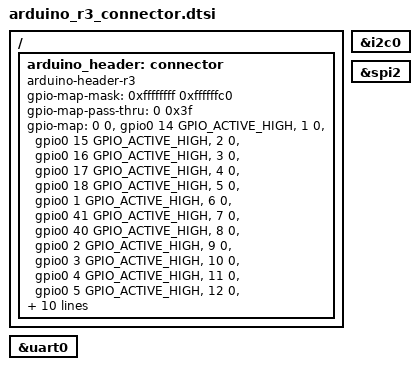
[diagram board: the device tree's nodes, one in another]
/*
 * Copyright 2023 Google LLC
 *
 * SPDX-License-Identifier: Apache-2.0
 */

/ {
	arduino_header: connector {
		/*
		* Note: UART pins TX and RX are swapped on this board
		* compared to the original Arduino Uno R3 header.
		* This file complies with the names in the silkscreen
		* and official Adafruit documentation, and must be
		* corrected with an overlay in cases where interfacing
		* with compatible Arduino shields that use UART.
		*/
		compatible = "arduino-header-r3";
		#gpio-cells = <2>;
		gpio-map-mask = <0xffffffff 0xffffffc0>;
		gpio-map-pass-thru = <0 0x3f>;
		gpio-map = <0  0 &gpio0 14 GPIO_ACTIVE_HIGH>, /* A0 */
		<1  0 &gpio0 15 GPIO_ACTIVE_HIGH>, /* A1 */
		<2  0 &gpio0 16 GPIO_ACTIVE_HIGH>, /* A2 */
		<3  0 &gpio0 17 GPIO_ACTIVE_HIGH>, /* A3 */
		<4  0 &gpio0 18 GPIO_ACTIVE_HIGH>, /* A4 */
		<5  0 &gpio0 1  GPIO_ACTIVE_HIGH>, /* A5 */
		<6  0 &gpio0 41 GPIO_ACTIVE_HIGH>, /* D0 */
		<7  0 &gpio0 40 GPIO_ACTIVE_HIGH>, /* D1 */
		<8  0 &gpio0 2  GPIO_ACTIVE_HIGH>, /* D2 */
		<9  0 &gpio0 3  GPIO_ACTIVE_HIGH>, /* D3 */
		<10 0 &gpio0 4  GPIO_ACTIVE_HIGH>, /* D4 */
		<11 0 &gpio0 5  GPIO_ACTIVE_HIGH>, /* D5 */
		<12 0 &gpio0 6  GPIO_ACTIVE_HIGH>, /* D6 */
		<13 0 &gpio0 7  GPIO_ACTIVE_HIGH>, /* D7 */
		<14 0 &gpio0 8  GPIO_ACTIVE_HIGH>, /* D8 */
		<15 0 &gpio0 9  GPIO_ACTIVE_HIGH>, /* D9 */
		<16 0 &gpio0 10 GPIO_ACTIVE_HIGH>, /* D10 / SPI CS */
		<17 0 &gpio0 11 GPIO_ACTIVE_HIGH>, /* D11 / SPI COPI */
		<18 0 &gpio0 12 GPIO_ACTIVE_HIGH>, /* D12 / SPI CIPO */
		<19 0 &gpio0 13 GPIO_ACTIVE_HIGH>, /* D13 / SPI SCK  */
		<20 0 &gpio0 47 GPIO_ACTIVE_HIGH>, /* D14 / I2C SDA  */
		<21 0 &gpio0 48 GPIO_ACTIVE_HIGH>; /* D15 / I2C SCL  */
	};

};

arduino_i2c: &i2c0 {};
arduino_spi: &spi2 {};
arduino_serial: &uart0 {};
